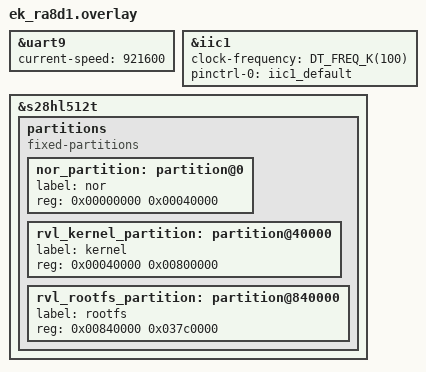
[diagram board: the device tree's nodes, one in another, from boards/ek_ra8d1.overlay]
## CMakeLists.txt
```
cmake_minimum_required(VERSION 3.20.0)
find_package(Zephyr REQUIRED HINTS $ENV{ZEPHYR_BASE})
project(ra8d1_tinyemu)

# emu/ is portable C99 and knows nothing about Zephyr or this board. The same
# files are compiled unchanged by host/Makefile for the Mac test harness, so
# nothing in here may include a Zephyr header. Everything emu/ needs from the
# outside it asks for through emu/rv_platform.h.
target_sources(app PRIVATE
	emu/riscv_cpu.c
	emu/rv_iomem.c
	emu/rv_hostsbi.c
	emu/rv_fdt.c
	emu/rv_machine.c
	emu/rv_virtio.c
)

# Guest floating point. See notes/00-port.md section "Float".
#
# The rv32 Buildroot guest we have is built for the ilp32d ABI, so its glibc
# and every binary linked against it execute F and D instructions. With
# TINYEMU_FLEN=0 those are illegal instructions and init dies with SIGILL -
# observed, not predicted. 64 is therefore the default; drop it to 0 and save
# the flash below only once the guest userspace is rebuilt soft-float.
set(TINYEMU_FLEN 64 CACHE STRING "Guest FP register width: 0, 32 or 64")

if(NOT TINYEMU_FLEN EQUAL 0)
	target_sources(app PRIVATE emu/softfp.c)
	set_source_files_properties(emu/softfp.c
		PROPERTIES COMPILE_OPTIONS "-Wno-unused-parameter;-Wno-sign-compare")
endif()

# src/ is the platform shim plus glue. platform_zephyr.c is the only file that
# knows what board this is, and it takes its facts from devicetree.
target_sources(app PRIVATE
	src/main.c
	src/platform_zephyr.c
)

# The guest console over TCP. Nothing under emu/ is involved: the bridge sits
# behind plat_putc()/plat_getc() in platform_zephyr.c, so the host harness and
# a no-networking build both compile without it. src/telnet.h stubs the whole
# interface to inline no-ops when CONFIG_NETWORKING is off, which is what keeps
# main.c and platform_zephyr.c free of #ifdefs.
target_sources_ifdef(CONFIG_NETWORKING app PRIVATE src/telnet.c)

# The TCP image loader, speaking the protocol rvlinux's pushimage.py already
# tests. Same arrangement: src/pusher.h stubs its interface to inline no-ops
# when it is off, so main.c has no #ifdefs. Unlike telnet.c this one is guarded
# on its own symbol rather than on CONFIG_NETWORKING, because the flash
# accessors it needs from platform_zephyr.c are compiled unconditionally and
# nothing else in a no-pusher build has any use for a listener.
target_sources_ifdef(CONFIG_RVT_PUSHER app PRIVATE src/pusher.c)

# The guest's NIC: the emulated device (portable, harness stubs it) and the
# Zephyr backend that bridges it onto eth0 in promiscuous mode. The device
# file compiles unconditionally - with no backend, plat_net_mac() returns
# false and the device is never instantiated, same rule as the block device
# with no rootfs.
target_sources(app PRIVATE emu/rv_virtio_net.c)
target_sources_ifdef(CONFIG_RVT_GUEST_NET app PRIVATE src/netbridge.c)

target_include_directories(app PRIVATE src emu emu/shim)

# TinyEMU build-time configuration.
#
#   MAX_XLEN=32 / CONFIG_RISCV_MAX_XLEN=32
#       Build only the RV32 template. The 64- and 128-bit instantiations are
#       separate translation units upstream and are simply not compiled.
#   FLEN
#       Width of the guest's FP registers, from TINYEMU_FLEN above. At 0 every
#       "#if FLEN > 0" block disappears and softfp.c is not compiled at all.
#       The value also feeds misa, which feeds the generated devicetree's
#       riscv,isa - there is no second place to keep in step.
#   USE_GLOBAL_STATE
#       Upstream guards a static RISCVCPUState behind this (riscv_cpu.c:57)
#       for the emscripten build. Defining it here is what replaces the one
#       and only mallocz() in the core with a .bss object, so the emulator
#       does no dynamic allocation at all. See notes/00-port.md.
#   CONFIG_HOST_SBI
#       Enables the five-line hook in raise_exception2() that services the
#       guest's supervisor ecall in host C instead of in emulated M-mode
#       firmware. Also documented in notes/00-port.md.
target_compile_definitions(app PRIVATE
	MAX_XLEN=32
	CONFIG_RISCV_MAX_XLEN=32
	FLEN=${TINYEMU_FLEN}
	USE_GLOBAL_STATE
	CONFIG_HOST_SBI
)

# The vendored TinyEMU sources are not warning-clean under Zephyr's flags and
# we do not want to diverge from upstream just to silence them. Confine the
# suppression to the one file that needs it.
set_source_files_properties(emu/riscv_cpu.c
	PROPERTIES COMPILE_OPTIONS "-Wno-unused-parameter;-Wno-sign-compare")
```

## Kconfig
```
# Application options.
#
# Zephyr uses this file as the Kconfig root when it exists in the application
# directory, so it must pull in the tree's own Kconfig at the end.

mainmenu "TinyEMU rv32 Sv32 Linux on EK-RA8D1"

config RVT_CMDLINE
	string "Guest kernel command line"
	default "console=ttyS0,115200 earlycon=sbi root=/dev/vda ro rootfstype=ext2"
	help
	  Placed in the generated devicetree as /chosen/bootargs.

	  The default assumes the rootfs slot holds an ext2 image, which is
	  what Buildroot produces and what the guest kernel can mount - it has
	  ext2 and ext4 built in and, checked against the image, no EROFS and
	  no squashfs. `ro` is not optional: the block device offers
	  VIRTIO_BLK_F_RO and rejects writes.

	  earlycon=sbi gets output from the very first line, before the 8250
	  driver exists, through the SBI debug console in emu/rv_hostsbi.c.

config RVT_FORCE_SELFTEST
	bool "Always run the built-in RV32 self-test"
	default n
	help
	  Ignore the kernel slot and boot src/testrom.h regardless of what is
	  in flash. The self-test is otherwise only reached when the slot holds
	  nothing bootable.

	  This is how the emulator gets characterised on a board whose flash
	  holds a guest it cannot boot, which is the normal state until a
	  kernel small enough for the 8 MB slot exists.

config RVT_CRC_ROOTFS
	bool "Verify the rootfs CRC at boot"
	default n
	help
	  The kernel slot is always verified: a half-written kernel otherwise
	  surfaces as a crash somewhere unrelated. The rootfs is not, by
	  default, because it is tens of megabytes of OSPI reads on every boot
	  to catch a corruption the filesystem itself would also catch.

	  Worth turning on while bringing up a new push path.

config RVT_UART_RX_RING
	int "Console receive ring filled by the UART ISR, in bytes"
	default 1024
	depends on UART_INTERRUPT_DRIVEN
	help
	  The guest reads the console once per emulator slice (RV_SLICE_INSNS
	  instructions, ~667 us at 15.37 MIPS) and uart_poll_in() holds one
	  byte between reads, so without an ISR and this ring a pasted line
	  loses most of its bytes. Losing the newline hangs the guest shell in
	  read() forever, which is why the symptom is a dead console rather
	  than mistyped input - BUILD.md gotcha 17.

	  Size it for the longest line pasted in one go. 1024 covers a
	  base64-encoded file chunk; the default emulator-side 8250 ring is
	  only 64 bytes but drains every slice, so it is not the constraint.

config RVT_EMU_PRIORITY
	int "Priority of the thread running the emulator step loop"
	default 10
	depends on NETWORKING
	help
	  rv_machine_run_bounded() never blocks and never yields - a guest WFI
	  returns early from riscv_cpu_interp() and spins - so with Zephyr's
	  priority-based preemption any thread numerically above it would never
	  run at all. The Renesas Ethernet RX thread sits at priority 2 and the
	  TCP worker at 2, so main() lowers itself to this value before the
	  image check. Guest instructions then run only in the time the network
	  stack does not want, which is nearly all of it.

menu "Guest telnet console"

config RVT_TELNET
	bool "Serve the guest console over TCP"
	default y
	depends on NETWORKING && NET_SOCKETS && NET_TCP && NET_IPV4
	help
	  Every byte of the guest's console already passes through
	  plat_putc()/plat_getc() - the 8250 model in emu/rv_machine.c and the
	  SBI debug console in emu/rv_hostsbi.c both go through them - so this
	  option adds a TCP listener that takes over both ends while a client
	  is attached, and a plain `telnet <board-ip>` lands on the guest's
	  root shell. Nothing under emu/ changes and nothing in the guest can
	  tell.

	  With no client attached the console falls back to the physical UART,
	  which is how the board is debugged.

if RVT_TELNET

config RVT_TELNET_PORT
	int "TCP port"
	default 23

config RVT_TELNET_TX_RING
	int "Guest-to-client buffer, bytes (power of two)"
	default 8192
	help
	  Sized to absorb a kernel boot log burst without dropping. The
	  emulator never blocks on this ring; once it is full, further guest
	  output is discarded and counted, which is the only policy that does
	  not risk stalling guest execution behind a TCP retransmit timeout.

config RVT_TELNET_RX_RING
	int "Client-to-guest buffer, bytes (power of two)"
	default 1024

config RVT_TELNET_MIRROR_UART
	bool "Also copy guest output to the UART while a client is attached"
	default n
	help
	  Handy when debugging the bridge itself. Costs one uart_poll_out()
	  per guest character on the emulator's hot path, which at 921600 baud
	  is about 11 us of busy-wait per byte, so leave it off normally.

config RVT_TELNET_THREAD_PRIORITY
	int "Telnet thread priority"
	default 5
	help
	  Must outrank RVT_EMU_PRIORITY and rank below the networking threads
	  at 2.

config RVT_TELNET_THREAD_STACK
	int "Telnet thread stack size"
	default 4096

endif # RVT_TELNET

endmenu

menu "TCP image pusher"

config RVT_PUSHER
	bool "Serve the RA8LDR image loader over TCP"
	default y
	depends on NETWORKING && NET_SOCKETS && NET_TCP && NET_IPV4 && FLASH
	select REBOOT
	help
	  Accept guest images on a TCP port, in the same wire format the
	  rvlinux app on this board already serves, so
	  ra8d1-linux/rvlinux/tools/pushimage.py drives this build unchanged.
	  Without it the only way to replace a guest image is to flash the
	  other application, push, and flash back - BUILD.md gotcha 14, which
	  costs a working board every time someone forgets that the two apps
	  boot different kernels.

	  REBOOT is selected rather than assumed: unlike rvlinux, a push here
	  stops the guest (see src/pusher.c) and the board has to restart to
	  bring it back.

if RVT_PUSHER

config RVT_PUSHER_PORT
	int "TCP port"
	default 5555
	help
	  pushimage.py's default. Changing it means passing HOST:PORT to the
	  tool, which it supports.

config RVT_PUSHER_REBOOT_DELAY_S
	int "Seconds after a successful push before the board reboots"
	default 30
	help
	  A push stops the guest, so the board has to reboot for the new image
	  to run. It is deferred rather than immediate because the normal
	  operation is two pushes back to back - kernel, then rootfs - and
	  rebooting between them would boot a new kernel against the old
	  rootfs and make the operator wait out DHCP before the second push.
	  Any connection arriving inside the window pushes the deadline out
	  again, so the board restarts once the pushing stops.

	  0 disables the automatic reboot entirely; the board then sits with a
	  stopped guest until it is reset.

config RVT_PUSHER_HALT_MS
	int "Milliseconds to wait for the emulator to stop before refusing"
	default 5000
	help
	  rv_request_poweroff() takes effect at the next instruction-slice
	  boundary, which is ~667 us at the measured 15.37 MIPS, so this is
	  three orders of magnitude of headroom. It is a bound rather than a
	  wait because the alternative to timing out is erasing flash while
	  the guest is still reading it.

config RVT_PUSHER_BLANK_CHECK
	bool "Verify a slot really is blank after erasing it"
	default y
	help
	  NOR erase reports success on a status bit and nothing checks that the
	  bits actually went to 1. A program can only clear bits, so writing
	  over an incompletely erased block yields the bitwise AND of old and
	  new: data that is present, stable across reads, and wrong - and
	  indistinguishable from a bad write once the payload is on top of it.
	  Checking before the first payload byte separates the two faults, at
	  the cost of one read pass over the erased region.

config RVT_PUSHER_VERIFY_ATTEMPTS
	int "How many times to read back and CRC a slot before failing a push"
	default 3
	help
	  A CRC32 that matches is worth trusting however many attempts it took,
	  so if any pass agrees the payload is right and the earlier passes were
	  bad reads. The count is the real product: pushes that routinely need a
	  second pass mean reads are marginal, which is a much more specific
	  finding than "verify failed".

	  Read attempts only. Nothing is rewritten between them and nothing may
	  be - this is Semper NOR with ECC over 16-byte units, and programming a
	  unit twice without an erase between corrupts it. A push that exhausts
	  its attempts fails, and pushimage.py's retry erases the slot first.

config RVT_PUSHER_RX_TIMEOUT_S
	int "Seconds a stalled transfer is tolerated before the push is dropped"
	default 30
	help
	  Per recv() call. Not a bound on filling a whole buffer - see
	  RVT_PUSHER_BUFFER_MS, which is the one that catches a trickle.

config RVT_PUSHER_BUFFER_MS
	int "Milliseconds allowed to fill one receive buffer before giving up"
	default 60000
	help
	  RVT_PUSHER_RX_TIMEOUT_S bounds a single recv(); this bounds the whole
	  buffer. Without it a sender delivering any bytes at all more often
	  than the per-recv timeout keeps the fill loop alive indefinitely
	  while the payload offset never advances - no progress line, no stall
	  report, nothing on the console. Four 54 MB pushes died exactly that
	  way before this existed.

	  A healthy buffer arrives in about 115 ms at the measured 71 KB/s, so
	  60 s is 500x headroom and only fires on a genuinely wedged transfer.
	  The report names bytes received and recv calls taken: one byte per
	  call is a TCP zero-window persist probe, which is the shape this was
	  built to catch.

config RVT_PUSHER_STALL_MS
	int "Milliseconds to wait for the flash writer before declaring a stall"
	default 15000
	help
	  A buffer should come back in ~35 ms. Seconds means the flash operation
	  is not returning at all, which FSP can do - several of its register
	  waits are unbounded spins. The listener stops draining the socket
	  while it waits here, so an unbounded wait shows up on the host as a
	  mid-transfer stall with a silent, healthy-looking board.

config RVT_PUSHER_BUF
	int "Size of each of the two receive buffers, bytes"
	default 8192
	help
	  The socket fills one while the flash programs the other. Bigger
	  buffers mean longer aligned flash writes; two of these live in .bss
	  for the life of the application.

	  Must be a multiple of 16, and src/pusher.c BUILD_ASSERTs it: this part
	  computes ECC over 16-byte units and forbids programming one twice
	  without an erase between, so a buffer that did not end on a unit
	  boundary would have every write reprogram the unit the previous write
	  left half done.

config RVT_PUSHER_THREAD_PRIORITY
	int "Listener thread priority"
	default 7
	help
	  Between the telnet thread (5) and the emulator (10), and both bounds
	  matter.

	  Above the emulator because the banner and header exchange happen
	  while the guest is still running - the guest is only stopped once the
	  header validates - and the emulator loop never blocks or yields, so a
	  pusher at or below 10 would never be scheduled to read the header
	  that is going to stop it.

	  Below telnet because an attached console is interactive and a push is
	  not: the pusher spends minutes at a time inside flash operations, and
	  the console's 5 ms poll should keep winning through it.

config RVT_PUSHER_WRITER_PRIORITY
	int "Flash writer thread priority"
	default 8
	help
	  One below the listener, so draining the socket beats programming
	  flash when both are runnable. That is the right way round: the flash
	  is the slower end and TCP is what stalls if it is not read.

config RVT_PUSHER_THREAD_STACK
	int "Listener thread stack size"
	default 3072

config RVT_PUSHER_WRITER_STACK
	int "Flash writer thread stack size"
	default 2048

endif # RVT_PUSHER

endmenu

menu "Networking bring-up"
	depends on NETWORKING

config RVT_NET_STATIC_IP
	bool "Configure a static IPv4 address instead of using DHCP"
	default n

config RVT_NET_ADDR
	string "Static IPv4 address"
	default "192.168.1.50"
	depends on RVT_NET_STATIC_IP

config RVT_NET_NETMASK
	string "Static IPv4 netmask"
	default "255.255.255.0"
	depends on RVT_NET_STATIC_IP

config RVT_NET_GATEWAY
	string "Static IPv4 gateway"
	default "192.168.1.1"
	depends on RVT_NET_STATIC_IP

config RVT_NET_DHCP_WAIT_S
	int "Seconds to wait for DHCP before booting the guest"
	default 15
	depends on !RVT_NET_STATIC_IP
	help
	  Boot is held here only so the address can be printed on the console
	  before the guest's own output starts. On timeout the guest boots
	  anyway and DHCP keeps running in the background; the address is
	  printed whenever it does arrive.

config RVT_NET_FALLBACK_ADDR
	string "Static IPv4 address to apply if DHCP times out"
	default ""
	depends on !RVT_NET_STATIC_IP
	help
	  Leave empty to disable. DHCP is left running, so a lease arriving
	  later still takes effect.

config RVT_NET_FALLBACK_NETMASK
	string "Netmask for the DHCP fallback address"
	default "255.255.255.0"
	depends on !RVT_NET_STATIC_IP

endmenu

menu "Guest network interface"

config RVT_GUEST_NET
	bool "Give the guest a virtio-net NIC bridged to the real Ethernet"
	default y
	depends on NETWORKING && NET_L2_ETHERNET
	select NET_PROMISCUOUS_MODE
	select NET_SOCKETS_PACKET
	help
	  A virtio-net device in the emulated machine, backed by eth0 in
	  promiscuous mode: the guest gets its own MAC (the board's with the
	  local bit set and the last byte inverted) and its own DHCP lease on
	  the segment, so ssh/scp reach it directly. src/netbridge.c filters
	  the segment's traffic for the guest MAC, broadcast and multicast.

	  NET_PROMISCUOUS_MODE needs driver support - eth_renesas_ra.c gained
	  .set_config in the zephyr fork (8ca5eb88530); without that commit
	  this option prints "promiscuous mode REFUSED" and the guest NIC is
	  deaf. NET_SOCKETS_PACKET is what makes ethernet L2 transmit the
	  guest's raw frames verbatim (ethernet.c "Raw packet, just send it").

if RVT_GUEST_NET

config RVT_NET_GUEST_RX_RING
	int "Wire-to-guest frame ring, bytes (power of two)"
	default 8192
	help
	  Holds length-prefixed whole frames between the promiscuous RX
	  thread and the emulator's once-per-slice poll. Five full-size
	  frames; a burst beyond that is dropped and counted, which is what a
	  real NIC with a full ring does too.

config RVT_NET_GUEST_THREAD_PRIORITY
	int "Filter thread priority"
	default 6
	help
	  Below telnet (5), above the emulator (10): a flood of segment
	  traffic must not starve the console, but filtering must still
	  preempt the guest or the ring only drains at slice boundaries.

config RVT_NET_GUEST_THREAD_STACK
	int "Filter thread stack size"
	default 2048

endif # RVT_GUEST_NET

endmenu

source "Kconfig.zephyr"
```

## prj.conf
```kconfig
# Emulated MMU RISC-V Linux host app - board-neutral configuration.
#
# Everything here is true of the app on any Zephyr board. Board-specific
# symbols live in boards/<board>.conf, which Zephyr merges on top of this
# file. If a symbol's name contains a vendor or a part number it belongs
# there, not here.

CONFIG_PRINTK=y
CONFIG_BOOT_BANNER=n

# Interrupt-driven console receive. Not a tuning knob: with polled input the
# guest samples the UART once per emulator slice (~667 us) and holds one byte,
# so a line pasted at wire speed loses its newline and hangs the guest shell
# forever. Measured identically at 921600 and 460800, which is what ruled out
# the baud rate. See CONFIG_RVT_UART_RX_RING and BUILD.md gotcha 17.
CONFIG_UART_INTERRUPT_DRIVEN=y

# main() runs the emulator directly. The stack holds only main's own frame
# plus the interpreter's, which is shallow: the CPU state and every device is
# in .bss. The one large frame is the virtio descriptor chain, which is
# VIRTIO_MAX_CHAIN * 16 bytes.
CONFIG_MAIN_STACK_SIZE=8192

# Both images are read through the memory-mapped flash window, not through
# flash_read(), so no driver call is on the path. The driver still has to be
# built and to run: it is what puts the octo-SPI controller into octal DTR
# mode, and without that the memory-mapped window does not work at all.
CONFIG_FLASH=y

# crc32_ieee() for the image check.
CONFIG_CRC=y

# Paravirt I/O bridge: the guest drives these through MMIO at 0x11200000.
CONFIG_GPIO=y
CONFIG_I2C=y

CONFIG_SPEED_OPTIMIZATIONS=y

# --------------------------------------------------------------- networking
#
# Only here to carry the guest console over TCP, so `telnet <board-ip>` lands
# on the guest's shell. The guest kernel has no IP stack of its own and does
# not need one: this is the *host* stack, and plat_putc()/plat_getc() - which
# are both ends of the guest's console already - get routed to a socket.
#
# The vendor Ethernet, MDIO and PHY driver symbols live in
# boards/ek_ra8d1.conf, per the rule at the top of this file. CONFIG_NETWORKING
# is what makes their menus exist at all: they default y off the devicetree,
# but the menus only appear once NET_L2_ETHERNET is on.
CONFIG_NETWORKING=y
CONFIG_NET_L2_ETHERNET=y
CONFIG_NET_IPV4=y
CONFIG_NET_IPV6=n
CONFIG_NET_TCP=y
CONFIG_NET_UDP=y
CONFIG_NET_SOCKETS=y
CONFIG_NET_DHCPV4=y
CONFIG_NET_ARP=y

# Pool sizes, and the RX side is load-bearing in a way that cost a night to
# find. Zephyr derives the TCP receive window as (NET_BUF_RX_COUNT *
# NET_BUF_DATA_SIZE) / 3 when MAX_RECV_WINDOW_SIZE is 0, so the old
# NET_BUF_RX_COUNT=32 gave (32*128)/3 = 1365 bytes - LESS THAN ONE MSS.
# Every full-size segment slammed the window shut, every next segment
# depended on one window-update ACK, and losing a single one deadlocked the
# connection permanently, because tcp_update_recv_wnd() only runs when the
# app reads more data and the app had already drained everything. A 54 MB
# push is ~40,000 of those round trips; five instrumented runs died at
# offsets scattered 6.5x apart, which is what a per-round-trip lottery looks
# like. rvlinux runs the same 1365-byte window and merely wins more rolls -
# its own historical intermittent push failures are consistent with the same
# knife edge.
#
# 256 buffers = 32 KB of RX pool, window pinned at 10922 = 7.5 MSS backed by
# a pool 3x its size. ~28 KB more SRAM, affordable at 12.9% used. Do NOT set
# MAX_RECV_WINDOW_SIZE above what the pool backs: a nonzero value REPLACES
# the derived one rather than capping it, which is how an earlier 16384
# "cap" actually advertised 4x the buffering the board owned and made
# everything worse.
CONFIG_NET_PKT_RX_COUNT=32
CONFIG_NET_PKT_TX_COUNT=16
CONFIG_NET_BUF_RX_COUNT=256
CONFIG_NET_BUF_TX_COUNT=32
CONFIG_NET_TCP_MAX_RECV_WINDOW_SIZE=10922
CONFIG_NET_MAX_CONTEXTS=6
CONFIG_NET_MAX_CONN=6

# Detect a client that vanished without a FIN, so the console reverts to the
# UART instead of staying wedged in "telnet attached" forever.
CONFIG_NET_TCP_KEEPALIVE=y

# TRIED AND REJECTED 2026-08-09, do not re-derive it:
# CONFIG_NET_TCP_MAX_RECV_WINDOW_SIZE=16384
#
# The reasoning was that a big receive window lets the host stream megabytes
# into the board's buffers, finish its send while the flash writer is minutes
# behind, and then time out during the silent drain - which is a real effect,
# and is why the first kernel push failed at 99.6% with the board reporting
# "rx error at offset 6561792 of 6577272". Capping the window to 16 KB was
# meant to make the sender's rate converge on the writer's so pushimage.py's
# default timeouts would work again.
#
# Measured: it made things worse. With the cap a 54 MB rootfs push stalled at
# 0.06 MB instead of 99.6%, and the two following attempts never got a banner.
# The end-of-payload drain is a host-side timeout question, answered with
# --rx-timeout 120 --commit-timeout 300, and not a reason to throttle the link.

# SO_RCVTIMEO. The image pusher enforces its own timeouts with zsock_poll() and
# does not depend on this, but it sets the option too and reports the failure if
# it is refused - on the rvlinux board a missing RCVTIMEO left the loader
# blocked in recv() forever, which wedged the whole service until a reset. Both
# halves are cheap; only one of them can be forgotten in a config file.
CONFIG_NET_CONTEXT_RCVTIMEO=y

# The emulator loop never blocks and never yields, so every networking thread
# must outrank it. main() drops itself to CONFIG_RVT_EMU_PRIORITY before the
# image check; see the comment there.
CONFIG_MAIN_THREAD_PRIORITY=0

# ------------------------------------------------------------------ debugging
#
# Catch a stack overflow instead of letting it corrupt whatever is below.
#
# On by default, not confined to a debug build, and the reason is the open bug:
# a 54 MB push takes the board down with no ping, no socket and NOTHING on the
# console, which is the signature of an escalated HardFault. Every wait in
# src/pusher.c is bounded and prints, so a board that merely got stuck would
# have said so - and with stack protection off, a thread that ran off the end
# of its stack is one of the few faults that stays silent.
#
# It is cheaper here than the usual quote suggests. On this Armv8-M core Zephyr
# satisfies it with CONFIG_BUILTIN_STACK_GUARD - the PSPLIM hardware stack
# limit register - not with CONFIG_MPU_STACK_GUARD, so it costs a register
# write per context switch and NO MPU region. Verified in the generated
# .config, not assumed.
#
# One consequence to expect rather than be surprised by: this can turn a board
# that appeared to work into one that faults at boot. That would be a real
# overflow that was previously corrupting memory silently, not a regression
# from enabling the check.
CONFIG_HW_STACK_PROTECTION=y
```

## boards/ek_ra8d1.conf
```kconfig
# EK-RA8D1 specific Kconfig.
#
# Merged on top of prj.conf (Zephyr appends prj.conf, then socs/, then
# boards/ - see cmake/modules/configuration_files.cmake).

# SDRAM controller. The board DTS marks &sdram okay but the memc driver class
# still has to be enabled, and nothing on this board does it for us.
CONFIG_MEMC=y

# D-cache is a 3.8x swing on SDRAM reads on this board (123 vs 32 MiB/s
# measured by the mini-rv32ima port), and guest RAM is SDRAM, so every guest
# load and store is on the other side of this switch.
CONFIG_ICACHE=y
CONFIG_DCACHE=y
CONFIG_CACHE_MANAGEMENT=y

# Ethernet, for the telnet console. All three default y off DT_HAS_*_ENABLED -
# &eth, &mdio and phy@5 are already status = "okay" in the board DTS - but they
# are stated explicitly so an upstream default change cannot quietly drop the
# link. Requires SW1-5 ON; SW1-7 (SDRAM) stays ON, which the Renesas switch
# table implies is exclusive and is not: verified, SDRAM still reports 64 MB.
#
# ETH_RENESAS_RA selects NOCACHE_MEMORY, which is load-bearing here rather than
# incidental: we run CONFIG_DCACHE=y, and without the nocache placement the
# EDMAC descriptors would be read through a stale cache line.
CONFIG_ETH_RENESAS_RA=y
CONFIG_MDIO=y
CONFIG_MDIO_RENESAS_RA=y
CONFIG_PHY_GENERIC_MII=y

# The default 1500 B is tight once the L2 path is inlined into this thread.
CONFIG_ETH_RA_RX_THREAD_STACK_SIZE=2048

# Entropy for TCP initial sequence numbers comes from the real TRNG rather
# than the timer fallback.
CONFIG_ENTROPY_RENESAS_RA=y
```

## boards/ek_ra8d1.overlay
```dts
/*
 * EK-RA8D1 wiring for the TinyEMU app.
 *
 * Everything here is specific to this board: node labels like `uart9`,
 * `s28hl512t` and `iic1` exist on the EK-RA8D1 and nowhere else. Porting
 * means writing a sibling `boards/<board>.overlay` and changing no source.
 *
 * Note there is deliberately no `app.overlay`. Zephyr picks the application
 * devicetree overlay by a fallback chain, not a merge, so once
 * `boards/<board>.overlay` exists an `app.overlay` would silently do nothing.
 */

/* Console at 921600 rather than 115200: the loader pushes multi-megabyte
 * images, and at 115200 that is ~6 minutes per push against ~40 s here. The
 * rvlinux app on this board runs its console here too, so one terminal
 * setting works for both.
 *
 * Halved to 460800 on 2026-08-08 while hunting the dead-console bug, then put
 * back: input broke at *exactly* the same 40-character line at both rates,
 * which is what ruled the baud rate out. The fault was polled receive, not
 * speed - see CONFIG_UART_INTERRUPT_DRIVEN in prj.conf. Do not re-halve this
 * hoping to fix console input; that experiment has been run.
 */
&uart9 {
	current-speed = <921600>;
};

/*
 * iic1 is the RIIC controller on P512 (SCL) / P511 (SDA). The board DTS wires
 * up its pinctrl but leaves it disabled, because on this board those pins are
 * the MIPI graphics expansion header (J58) and the DVP camera connector (J13)
 * and only a shield normally drives them. The paravirt I/O bridge exposes it
 * to the guest, so turn it on the same way the Renesas LCD shield overlays
 * do. 100 kHz rather than the board's Fast Mode Plus default: with flying
 * leads and whatever pull-ups the attached breakout brings, slow is the
 * setting that works.
 */
&iic1 {
	status = "okay";
	#address-cells = <1>;
	#size-cells = <0>;
	clock-frequency = <DT_FREQ_K(100)>;
	pinctrl-0 = <&iic1_default>;
	pinctrl-names = "default";
};

/*
 * Two image slots in the octo-SPI NOR, at exactly the offsets the rvlinux app
 * on this board already uses and its TCP pusher already writes:
 *
 *   0x0000000  CIRCUITPY filesystem, and the OSPI driver's autocalibration
 *              sector at 0x2000
 *   0x0040000  kernel, 8 MB, magic "RA8LINUX"
 *   0x0840000  rootfs, 55.75 MB, magic "RA8ROOTF"
 *
 * Adopting those offsets rather than claiming our own is the whole point: an
 * image pushed with the tested tool boots under this app unchanged, and the
 * two apps can share a board without either having to reflash the other's
 * images. src/platform_zephyr.c BUILD_ASSERTs the geometry so a well-meant
 * edit here cannot silently break that.
 *
 * The rootfs slot is deliberately enormous. It is read in place through the
 * memory-mapped window and never copied, so its size costs no SDRAM at all -
 * it costs only flash, and the flash is otherwise unused.
 */
&s28hl512t {
	/delete-node/ partitions;

	partitions {
		compatible = "fixed-partitions";
		#address-cells = <1>;
		#size-cells = <1>;

		/* CIRCUITPY, and the driver's autocalibration sector. */
		nor_partition: partition@0 {
			label = "nor";
			reg = <0x00000000 0x00040000>;
		};

		rvl_kernel_partition: partition@40000 {
			label = "kernel";
			reg = <0x00040000 0x00800000>;
		};

		rvl_rootfs_partition: partition@840000 {
			label = "rootfs";
			reg = <0x00840000 0x037c0000>;
		};
	};
};
```

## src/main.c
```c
/*
 * MMU-capable RISC-V Linux on the Renesas EK-RA8D1 (Cortex-M85 @ 480 MHz).
 *
 * Runs TinyEMU's RV32 core - Sv32 paging, S-mode, a 256-entry softmmu TLB -
 * over the board's 64 MB external SDRAM. The point of the MMU is not the MMU:
 * Buildroot gates python3 on BR2_USE_MMU, so an MMU guest is the shortest
 * path to Blinka on this board. See ra8d1-linux/notes/sv32-mmu.md for how
 * that was decided and notes/00-port.md for this port.
 *
 * The guest boots straight into S-mode. There is no OpenSBI or BBL image
 * underneath it; SBI is implemented in host C in emu/rv_hostsbi.c.
 *
 * Host memory map:
 *   0x68000000  64 MB SDRAM   guest RAM (the guest sees it at 0x80000000)
 *   0x90000000  64 MB OSPI    memory-mapped for reads
 *   0x90040000  kernel slot   "RA8LINUX"
 *   0x90840000  rootfs slot   "RA8ROOTF", read in place as virtio-blk vda
 *
 * The rootfs is never copied into SDRAM. It is handed to the block device as
 * a pointer into the OSPI window, which is what makes a 55 MB root filesystem
 * possible on a board with 64 MB of RAM that the kernel already wants 26 of.
 *
 * With an empty kernel slot the app boots a compiled-in RV32 self-test
 * instead (src/testrom.h), so a freshly flashed board says something true
 * about the emulator without anyone having to push an image first.
 */

#include <zephyr/kernel.h>
#include <zephyr/devicetree.h>
#include <zephyr/sys/crc.h>

#include <string.h>

#include "image.h"
#include "pusher.h"
#include "rv_hostsbi.h"
#include "rv_machine.h"
#include "rv_platform.h"
#include "rv_virtio.h"
#include "netbridge.h"
#include "telnet.h"
#include "testrom.h"

/* The on-flash image container lives in src/image.h, because src/pusher.c
 * writes what this file reads and the two must agree byte for byte - it is the
 * header the host tool parses. */
BUILD_ASSERT(sizeof(struct img_hdr) == IMG_HDR_SIZE,
	     "header must match what the rvlinux pusher writes");

/*
 * RISC-V Linux Image header magic (arch/riscv/include/asm/image.h), at +56.
 *
 * Checked before booting anything out of flash, because the kernel slot on
 * this board may well contain the *nommu* rv32ima image the rvlinux app uses.
 * That image carries the same "RA8LINUX" slot magic and a valid CRC, but it is
 * a machine-mode nommu kernel: this machine would enter it in S-mode and it
 * would die somewhere unhelpful. One four-byte comparison turns that from a
 * mystery into a sentence on the console.
 */
#define RV_IMAGE_MAGIC2     0x05435352u  /* "RSC\x05" */
#define RV_IMAGE_MAGIC2_OFF 56U
#define RV_IMAGE_TEXTOFF_OFF 8U

/*
 * On rv32, arch/riscv/kernel/head.S sets text_offset to 0 for a
 * CONFIG_RISCV_M_MODE build and 0x400000 otherwise. That makes it a reliable
 * marker for the nommu, machine-mode kernel the rvlinux app boots - which
 * carries the same slot magic, the same Image magic and a perfectly good CRC,
 * and which this machine would enter in S-mode and hang. Found the hard way:
 * the first boot on real silicon did exactly that.
 */
#define RV_IMAGE_MMODE_TEXT_OFFSET 0

/* ------------------------------------------------------------------ output
 *
 * The application's own banner and diagnostics, always on the physical UART.
 * Not plat_putc(): that is the *guest's* console and follows a telnet client
 * when one is attached, which is exactly where these lines must not go.
 */

static void up(char c)
{
	plat_uart_putc(c);
}

static void us(const char *s)
{
	plat_uart_puts(s);
}

static void udec(uint64_t v)
{
	char buf[24];
	int n = 0;

	if (v == 0) {
		up('0');
		return;
	}
	while (v > 0 && n < (int)sizeof(buf)) {
		buf[n++] = (char)('0' + (v % 10));
		v /= 10;
	}
	while (n-- > 0) {
		up(buf[n]);
	}
}

static void uhex(uint32_t v)
{
	int i;

	us("0x");
	for (i = 28; i >= 0; i -= 4) {
		uint32_t d = (v >> i) & 0xf;

		up((char)(d < 10 ? '0' + d : 'a' + d - 10));
	}
}

/* ------------------------------------------------------------- slot check */

/*
 * Validate one slot in place, straight out of the memory-mapped flash window.
 * Returns the payload pointer and sets *len, or NULL.
 *
 * The CRC costs one pass over the image at boot - about 26 MB for the kernel
 * and 55 for the rootfs, which is not free. It is still worth it for the
 * kernel: a half-written image otherwise shows up as a crash somewhere
 * unrelated, which is far more expensive to debug than a slow boot.
 *
 * For the rootfs it is optional and off by default (CONFIG_RVT_CRC_ROOTFS),
 * because the failure it catches is one the filesystem also catches, and 55 MB
 * of OSPI reads on every boot is a real cost for a second opinion.
 */
static const uint8_t *slot_check(int slot, uint32_t *len, uint32_t *ms,
				 bool verify)
{
	size_t slot_size;
	const uint8_t *base = plat_slot_base(slot, &slot_size);
	const struct img_hdr *h;
	const uint8_t *payload;
	int64_t t0;

	*ms = 0;
	if (base == NULL || slot_size <= IMG_PAYLOAD_OFF) {
		return NULL;
	}
	h = (const struct img_hdr *)base;
	if (memcmp(h->magic, img_slot_magic(slot), 8) != 0) {
		return NULL;
	}
	if (h->len == 0 || h->len > slot_size - IMG_PAYLOAD_OFF) {
		return NULL;
	}

	payload = base + IMG_PAYLOAD_OFF;
	if (verify) {
		t0 = k_uptime_get();
		if (crc32_ieee(payload, h->len) != h->crc) {
			return NULL;
		}
		*ms = (uint32_t)(k_uptime_get() - t0);
	}
	*len = h->len;
	return payload;
}

/* -------------------------------------------------------------------- main */

int main(void)
{
	RVBootImage img;
	size_t ram_size;
	uint32_t klen = 0, rlen = 0, kms = 0, rms = 0;
	const uint8_t *kernel, *rootfs;
	uint64_t insns;
	int64_t t0;
	uint32_t sbi_calls, sbi_unsupported;
	int ret;

	/* Before the first banner byte, so nothing typed at the console is
	 * lost while the CRCs run. */
	plat_console_init();

	us("\r\n\r\nra8d1-tinyemu: rv32 Sv32 Linux host\r\n");
	us("host: cortex-m85 @ ");
	udec(sys_clock_hw_cycles_per_sec() / 1000000U);
	us(" MHz, sdram ");
	(void)plat_guest_ram(&ram_size);
	udec(ram_size / (1024 * 1024));
	us(" MB\r\n");

	/*
	 * Network first, before the image CRCs and long before the guest, so
	 * the address is printed while the console is still quiet. Both calls
	 * are no-ops when networking is off.
	 */
	rvt_net_bringup();
	rvt_telnet_start();
	/* Promiscuous RX on, filter thread up, before the guest boots - its
	 * first DHCP DISCOVER should find a wire already listening. */
	rvt_netbridge_start();

	/*
	 * The image loader, on its own port. Started here rather than after the
	 * slot checks so that a board holding an image it cannot boot is still
	 * reachable to be re-imaged - which is the case where a pusher is worth
	 * the most. It waits for an address of its own accord.
	 */
	rvt_pusher_start();

	/*
	 * Everything from here on either CRCs megabytes out of the OSPI window
	 * or runs guest instructions, and neither blocks nor yields. Zephyr
	 * schedules preemptible threads strictly by priority, so at the default
	 * priority 0 this thread would starve the Ethernet RX thread (2), the
	 * TCP worker (2) and the telnet thread (5) -- for the whole life of the
	 * guest, which is to say forever. Drop below all of them and let the
	 * network stack preempt at will; a few microseconds of stolen guest
	 * time per packet is unmeasurable, a dropped packet is not.
	 *
	 * Dropped before the image check rather than just before the step loop
	 * because a full-slot CRC is seconds of uninterrupted work on its own.
	 */
	rvt_emu_priority_drop();

	memset(&img, 0, sizeof(img));

	kernel = IS_ENABLED(CONFIG_RVT_FORCE_SELFTEST)
			 ? NULL
			 : slot_check(PLAT_SLOT_KERNEL, &klen, &kms, true);
	rootfs = slot_check(PLAT_SLOT_ROOTFS, &rlen, &rms,
			    IS_ENABLED(CONFIG_RVT_CRC_ROOTFS));

	/*
	 * A valid slot is not the same as a bootable kernel. Reject anything
	 * without the RISC-V Image magic rather than jumping into it.
	 */
	if (kernel != NULL) {
		uint32_t magic2 = 0;

		if (klen >= 64) {
			memcpy(&magic2, kernel + RV_IMAGE_MAGIC2_OFF,
			       sizeof(magic2));
		}
		if (magic2 == RV_IMAGE_MAGIC2 && klen >= 64) {
			uint32_t toff = 0;

			memcpy(&toff, kernel + RV_IMAGE_TEXTOFF_OFF,
			       sizeof(toff));
			if (toff == RV_IMAGE_MMODE_TEXT_OFFSET) {
				us("kernel: slot holds ");
				udec(klen);
				us(" B, a valid rv32 Image but an M-mode"
				   " (nommu) build -- that is the rvlinux"
				   " guest, and this machine boots S-mode"
				   " kernels\r\n");
				kernel = NULL;
			}
		}

		if (kernel != NULL && magic2 != RV_IMAGE_MAGIC2) {
			us("kernel: slot holds ");
			udec(klen);
			us(" B with a good CRC, but ");
			if (klen >= 2 && kernel[0] == 0x1f && kernel[1] == 0x8b) {
				/* The rvlinux pusher sends Image.gz, because a
				 * raw 25.9 MB Image does not fit an 8 MB slot.
				 * Nothing here decompresses yet. */
				us("it is gzipped and this app has no"
				   " decompressor");
			} else {
				us("it has no RISC-V Image header -- most"
				   " likely the nommu image from the rvlinux"
				   " app, which this machine cannot boot");
			}
			us("\r\n");
			kernel = NULL;
		}
	}

	if (kernel != NULL) {
		img.kernel = kernel;
		img.kernel_size = klen;
		us("kernel: ");
		udec(klen);
		us(" B, crc ok in ");
		udec(kms);
		us(" ms\r\n");
	} else {
		/*
		 * Nothing bootable in flash. Rather than stop, run the
		 * compiled-in RV32 self-test, which exercises the CPU, the
		 * SBI layer, the generated devicetree and the Sv32 walk and
		 * prints a verdict. On a board nobody has pushed to yet that
		 * is the most useful thing this app can do.
		 */
		us("kernel: no valid image in flash; running the built-in "
		   "self-test instead\r\n");
		img.kernel = testrom;
		img.kernel_size = sizeof(testrom);
		img.cmdline = "";
		rootfs = NULL;
	}

	if (rootfs != NULL && img.kernel != testrom) {
		img.rootfs = rootfs;
		img.rootfs_size = rlen;
		us("rootfs: ");
		udec(rlen / (1024 * 1024));
		us(" MB, read in place from OSPI");
		if (rms != 0) {
			us(", crc ok in ");
			udec(rms);
			us(" ms");
		}
		us("\r\n");
	} else if (img.kernel != testrom) {
		us("rootfs: none; the guest will need a root= it can reach\r\n");
	}

	if (img.cmdline == NULL) {
		img.cmdline = CONFIG_RVT_CMDLINE;
	}

	ret = rv_machine_init(&img);
	if (ret != 0) {
		us("rv_machine_init failed: errno ");
		udec((uint32_t)(-ret));
		us("\r\n");
		/*
		 * No guest will ever run, so tell the pusher the board is
		 * already quiescent. Without this a push would wait out its
		 * halt timeout and refuse - on exactly the board that most
		 * needs a new image.
		 */
		(void)rvt_pusher_guest_halted();
		return 0;
	}

	{
		uint32_t fdt_size = 0;
		uint32_t fdt_addr = rv_machine_fdt(&fdt_size);

		us("guest: ram 0x80000000+");
		udec(ram_size / (1024 * 1024));
		us(" MB, dtb at ");
		uhex(fdt_addr);
		us(" (");
		udec(fdt_size);
		us(" B)");
		if (rv_virtio_blk_sectors() != 0) {
			us(", vda ");
			udec(rv_virtio_blk_sectors());
			us(" sectors");
		}
		us("\r\n--- guest output follows ---\r\n");
	}

	t0 = k_uptime_get();
	ret = rv_machine_run();
	insns = rv_machine_insns();

	/*
	 * Whatever stopped the guest, tell the pusher: it may be blocked
	 * waiting for exactly this, because the rootfs is read in place out of
	 * the flash a push has to erase. It answers true when the stop was its
	 * doing, which is not a poweroff and should not be reported as one.
	 */
	if (rvt_pusher_guest_halted()) {
		us("\r\n--- guest halted for an image push ---\r\n");
	} else {
		us("\r\n--- guest stopped (");
		us(ret == 1 ? "reboot" : "poweroff");
		us(") ---\r\n");
		if (ret == 1) {
			plat_reboot();
		} else {
			plat_poweroff();
		}
	}

	riscv_host_sbi_stats(&sbi_calls, &sbi_unsupported);
	us("insns ");
	udec(insns);
	us(" in ");
	udec((uint64_t)(k_uptime_get() - t0));
	us(" ms, sbi calls ");
	udec(sbi_calls);
	us(" (");
	udec(sbi_unsupported);
	us(" unsupported), blk requests ");
	udec(rv_virtio_blk_requests());
	us("\r\n");
	return 0;
}
```

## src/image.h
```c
/*
 * image.h - the on-flash image container, shared by the reader and the writer.
 *
 * Not ours. This is the layout the rvlinux app on this board already writes
 * and its TCP pusher already tests end to end: a 16-byte header at the slot
 * base and the payload from +4096. Keeping it byte-for-byte means an image
 * pushed with the working tool boots here unchanged.
 *
 * It lives in its own header because two files now depend on every byte of it
 * agreeing: src/main.c validates a slot at boot and src/pusher.c writes one.
 * They were duplicating the constants, which is a drift waiting to happen -
 * and the thing that would drift is the header the host tool parses.
 */
#ifndef RVT_IMAGE_H_
#define RVT_IMAGE_H_

#include <stdint.h>

#include "rv_platform.h"

#define IMG_HDR_SIZE    16U
#define IMG_PAYLOAD_OFF 4096U   /* the header gets its own aligned block */

struct img_hdr {
	char     magic[8];
	uint32_t len;
	uint32_t crc;
};

/*
 * The magic is per slot and is not redundant with the offset: it is what
 * catches a rootfs pushed into the kernel slot, which is a mistake worth eight
 * bytes of comparison to prevent.
 */
static inline const char *img_slot_magic(int slot)
{
	switch (slot) {
	case PLAT_SLOT_KERNEL:
		return "RA8LINUX";
	case PLAT_SLOT_ROOTFS:
		return "RA8ROOTF";
	default:
		return NULL;
	}
}

/*
 * Slot names as the host tool spells them. pushimage.py looks its --slot
 * argument up in the banner this produces, so these two strings are protocol,
 * not cosmetics.
 */
static inline const char *img_slot_name(int slot)
{
	switch (slot) {
	case PLAT_SLOT_KERNEL:
		return "kernel";
	case PLAT_SLOT_ROOTFS:
		return "rootfs";
	default:
		return "?";
	}
}

#endif /* RVT_IMAGE_H_ */
```

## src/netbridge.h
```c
/*
 * netbridge.h - guest NIC to real Ethernet, via promiscuous mode.
 *
 * See netbridge.c for the design and the why-not-CONFIG_NET_ETHERNET_BRIDGE
 * reasoning. The rv_platform.h side of this interface (plat_net_mac/send/
 * recv) is declared there; this header only carries the app-facing calls,
 * with the same stub-when-disabled pattern as telnet.h so main.c stays free
 * of #ifdefs.
 */
#ifndef NETBRIDGE_H_
#define NETBRIDGE_H_

#include <stdint.h>

#ifdef CONFIG_RVT_GUEST_NET

/* Turn on promiscuous RX, start the filter thread, open the guest's path to
 * the wire. Call after rvt_net_bringup(); before the guest boots, so its
 * first DHCP DISCOVER already has a wire to go out on. */
void rvt_netbridge_start(void);

/* Frames delivered to the guest; TX count and total drops via out-params. */
uint32_t rvt_netbridge_stats(uint32_t *tx, uint32_t *drops);

/*
 * Turn promiscuous RX back off, permanently, for the life of this boot.
 *
 * Called by the image pusher once it has stopped the guest. Promiscuous mode
 * is not free on the receive path: net_if_recv_data() does a full
 * net_pkt_clone() of EVERY frame the interface sees, and a 1514-byte frame is
 * 12 of the 32 net_bufs in the RX pool, so an in-flight frame plus its clone
 * is 24 of 32. During a multi-megabyte push that pressure is what the
 * transfer is competing against - and with the guest halted, every cloned
 * frame is filtered and freed without ever reaching it. See src/pusher.c and
 * notes/pusher.md.
 *
 * There is no resume: the guest cannot run again without a reboot, so nothing
 * would consume what the bridge delivers.
 */
void rvt_netbridge_suspend(void);

#else /* !CONFIG_RVT_GUEST_NET */

static inline void rvt_netbridge_start(void)
{
}

static inline void rvt_netbridge_suspend(void)
{
}

static inline uint32_t rvt_netbridge_stats(uint32_t *tx, uint32_t *drops)
{
	if (tx != NULL) {
		*tx = 0;
	}
	if (drops != NULL) {
		*drops = 0;
	}
	return 0;
}

#endif /* CONFIG_RVT_GUEST_NET */

#endif /* NETBRIDGE_H_ */
```

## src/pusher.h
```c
/*
 * pusher.h - the RA8LDR TCP image loader, and the flash access it needs.
 *
 * The board serves the same push protocol the rvlinux app on this board
 * already serves, on the same port, so ra8d1-linux/rvlinux/tools/pushimage.py
 * drives it unmodified. That tool is the reason the protocol is not being
 * improved: it is tested, it is what the operator's notes describe, and a
 * gratuitous change here would be a change to the one part of this system that
 * is known to work.
 *
 * The one behavioural difference from rvlinux is forced by this app: rvlinux
 * copies its guest out of flash at boot and never reads the window again, so a
 * push can land under a running guest. Here the rootfs is read IN PLACE out of
 * the memory-mapped OSPI window by virtio-blk for as long as the guest runs,
 * and an OSPI-B device cannot serve memory-mapped reads while a program or
 * erase is in progress. So a push stops the guest first and the board reboots
 * into the new image afterwards. See src/pusher.c for the full argument and
 * notes/pusher.md for what was considered instead.
 *
 * Everything degrades to an inline no-op when the pusher is compiled out, so
 * src/main.c carries no #ifdefs - the same arrangement as telnet.h.
 */
#ifndef RVT_PUSHER_H_
#define RVT_PUSHER_H_

#include <stdbool.h>
#include <stdint.h>

/* ------------------------------------------------------- flash for writing
 *
 * Implemented in src/platform_zephyr.c, which is the only file in this
 * application allowed to know what board this is. Reads go through the
 * memory-mapped window (plat_slot_base) and need none of this; erasing and
 * programming need the driver, and the driver needs offsets rather than
 * pointers.
 *
 * Declared unconditionally so that turning the pusher off does not silently
 * change what platform_zephyr.c provides.
 */
struct device;

/* The NOR the image slots live in, taken from the partition's parent node. */
const struct device *plat_flash_dev(void);

/*
 * A slot's offset in that device, and - through *writable - how much of it a
 * push may actually use. That is NOT always the devicetree partition size: see
 * the erase reserve in platform_zephyr.c. Returns UINT32_MAX for a bad slot.
 */
uint32_t plat_slot_offset(int slot, uint32_t *writable);

/* Erase granularity of the NOR, in bytes. */
uint32_t plat_flash_erase_size(void);

#ifdef CONFIG_RVT_PUSHER

/* Start the listener thread. Returns immediately; the thread waits for an
 * address of its own accord, exactly as the telnet thread does. */
void rvt_pusher_start(void);

/*
 * Called by main() once the emulator's run loop has returned, whatever stopped
 * it. Releases a push that is waiting for the guest to stop.
 *
 * Returns true if this app stopped the guest for a push, which is main()'s
 * cue to describe it as such rather than reporting a guest poweroff that did
 * not happen.
 */
bool rvt_pusher_guest_halted(void);

#else
static inline void rvt_pusher_start(void) { }
static inline bool rvt_pusher_guest_halted(void) { return false; }
#endif /* CONFIG_RVT_PUSHER */

#endif /* RVT_PUSHER_H_ */
```
